# S6E1B3xF register map
Vendor: Cypress; File version: 2.1
CPU: CM0PLUS r0p1, little endian, no MPU, no FPU, 2 interrupt priority bits
Registers are 8-bit, read-write, reset 0x0 unless marked. A register's access mark holds for its fields unless they carry their own. Offsets are from the block's base; [hi:lo] are bit positions; {n}, {i} and the like mark numbered series.

## CLK_GATING — Peripheral Clock Gating Registers
Base 0x4003C100
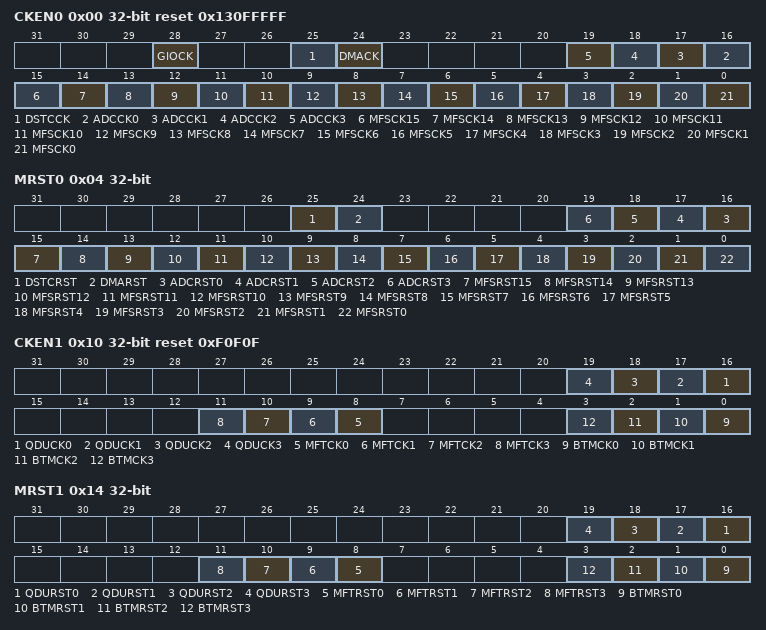
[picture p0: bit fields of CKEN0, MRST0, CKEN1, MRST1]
0x00 CKEN0 32-bit reset 0x130FFFFF — Peripheral Function Clock Control Register 0 [BHW]
  [28] GIOCK — Software clock control of GPIO/Fast GPIO function
  [25] DSTCCK — Software clock control of DSTC function
  [24] DMACK — Supplying and gating settings of DMAC operation clock
  [n+16] ADCCK{n} (n=0..3) — Settings for operation clock supplying and gating to A/D converter unit {n}
  [15] MFSCK15 — Settings for operation clock supply and gating to multi-function serial interface ch.15
  [14] MFSCK14 — Settings for operation clock supply and gating to multi-function serial interface ch.14
  [13] MFSCK13 — Settings for operation clock supply and gating to multi-function serial interface ch.13
  [12] MFSCK12 — Settings for operation clock supply and gating to multi-function serial interface ch.12
  [11] MFSCK11 — Settings for operation clock supply and gating to multi-function serial interface ch.11
  [10] MFSCK10 — Settings for operation clock supply and gating to multi-function serial interface ch.10
  [9] MFSCK9 — Settings for operation clock supply and gating to multi-function serial interface ch.9
  [8] MFSCK8 — Settings for operation clock supply and gating to multi-function serial interface ch.8
  [7] MFSCK7 — Settings for operation clock supply and gating to multi-function serial interface ch.7
  [6] MFSCK6 — Settings for operation clock supply and gating to multi-function serial interface ch.6
  [5] MFSCK5 — Settings for operation clock supply and gating to multi-function serial interface ch.5
  [4] MFSCK4 — Settings for operation clock supply and gating to multi-function serial interface ch.4
  [3] MFSCK3 — Settings for operation clock supply and gating to multi-function serial interface ch.3
  [2] MFSCK2 — Settings for operation clock supply and gating to multi-function serial interface ch.2
  [1] MFSCK1 — Settings for operation clock supply and gating to multi-function serial interface ch.1
  [0] MFSCK0 — Settings for operation clock supply and gating to multi-function serial interface ch.0
0x04 MRST0 32-bit — Peripheral Function Reset Control Register 0 [BHW]
  [25] DSTCRST — Reset control of DSTC
  [24] DMARST — Reset control of DMAC
  [n+16] ADCRST{n} (n=0..3) — Reset control of A/D converter unit {n}
  [15] MFSRST15 — Control of software reset of multi-function serial interface ch.15
  [14] MFSRST14 — Control of software reset of multi-function serial interface ch.14
  [13] MFSRST13 — Control of software reset of multi-function serial interface ch.13
  [12] MFSRST12 — Control of software reset of multi-function serial interface ch.12
  [11] MFSRST11 — Control of software reset of multi-function serial interface ch.11
  [10] MFSRST10 — Control of software reset of multi-function serial interface ch.10
  [9] MFSRST9 — Control of software reset of multi-function serial interface ch.9
  [8] MFSRST8 — Control of software reset of multi-function serial interface ch.8
  [7] MFSRST7 — Control of software reset of multi-function serial interface ch.7
  [6] MFSRST6 — Control of software reset of multi-function serial interface ch.6
  [5] MFSRST5 — Control of software reset of multi-function serial interface ch.5
  [4] MFSRST4 — Control of software reset of multi-function serial interface ch.4
  [3] MFSRST3 — Control of software reset of multi-function serial interface ch.3
  [2] MFSRST2 — Control of software reset of multi-function serial interface ch.2
  [1] MFSRST1 — Control of software reset of multi-function serial interface ch.1
  [0] MFSRST0 — Control of software reset of multi-function serial interface ch.0
0x10 CKEN1 32-bit reset 0xF0F0F — Peripheral Function Clock Control Register 1 [BHW]
  [n+16] QDUCK{n} (n=0..3) — Reset control of quad counter unit {n}
  [n+8] MFTCK{n} (n=0..3) — Settings for operation clock supply and gating of multi-function timer {n} and PPG {8n}/{8n+2}/{8n+4}/{8n+6}
  [n] BTMCK{n} (n=0..3) — Settings operation clock supply and gating to base timer {4n}/{4n+1}/{4n+2}/{4n+3}
0x14 MRST1 32-bit — Peripheral Function Reset Control Register 1 [BHW]
  [n+16] QDURST{n} (n=0..3) — Reset control of quad counter unit {n}
  [n+8] MFTRST{n} (n=0..3) — Control of multi-function timer {n} and PPG {8n}/{8n+2}/{8n+4}/{8n+6} reset control
  [n] BTMRST{n} (n=0..3) — Reset control of base timer {4n}/{4n+1}/{4n+2}/{4n+3}
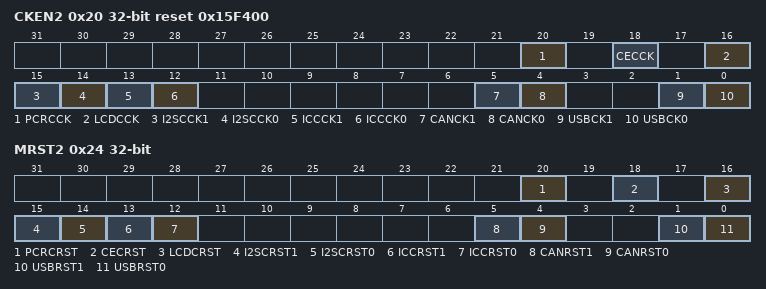
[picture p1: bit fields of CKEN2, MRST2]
0x20 CKEN2 32-bit reset 0x15F400 (reset mask 0x15F403) — Peripheral Function Clock Control Register 2 [BHW]
  [20] PCRCCK — Settings for clock supply and gating to Programmable-CRC
  [18] CECCK — Settings for clock supply and gating of HDMI-CEC/Remote Control Reception
  [16] LCDCCK — Settings for clock supply and gating to LCD Controller
  [15] I2SCCK1 — Settings for operation clock supply and gating of MFS I2S Interface ch.1
  [14] I2SCCK0 — Settings for operation clock supply and gating of MFS I2S Interface ch.0
  [13] ICCCK1 — Settings for operation clock supply and gating of IC Card Interface ch.1
  [12] ICCCK0 — Settings for operation clock supply and gating of IC Card Interface ch.0
  [5] CANCK1 — Settings for clock supply and gating to CAN controller ch.1
  [4] CANCK0 — Settings for clock supply and gating to CAN controller ch.0
  [1] USBCK1 — Settings for operation clock supply and gating of USB(function/host) ch.1
  [0] USBCK0 — Settings for operation clock supply and gating of USB(function/host) ch.0
0x24 MRST2 32-bit — Peripheral Function Reset Control Register 2 [BHW]
  [20] PCRCRST — Reset control of Programmable-CRC
  [18] CECRST — Reset control of HDMI-CEC/Remote Control Reception
  [16] LCDCRST — Reset control of LCD Controller
  [15] I2SCRST1 — Reset control of MFS I2S Interface ch.1
  [14] I2SCRST0 — Reset control of MFS I2S Interface ch.0
  [13] ICCRST1 — Reset control of IC Card Interface ch.1
  [12] ICCRST0 — Reset control of IC Card Interface ch.0
  [5] CANRST1 — Reset control of CAN controller ch.1
  [4] CANRST0 — Reset control of CAN controller ch.0
  [1] USBRST1 — Reset control of USB (function/host) ch.1
  [0] USBRST0 — Reset control of USB (function/host) ch.0
